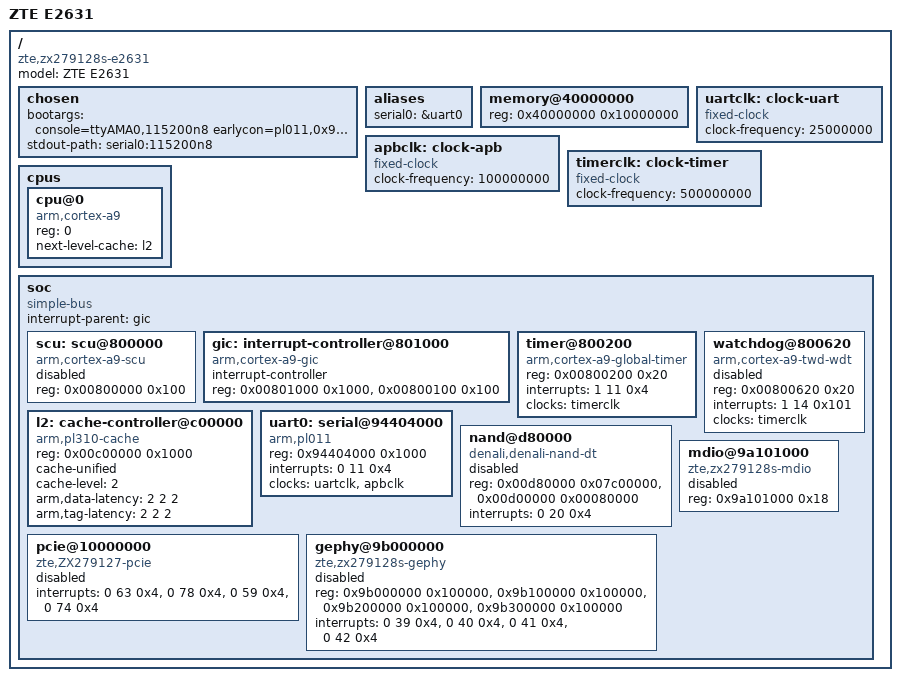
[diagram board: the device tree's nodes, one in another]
// SPDX-License-Identifier: GPL-2.0-only OR BSD-2-Clause
/dts-v1/;

/ {
	#address-cells = <1>;
	#size-cells = <1>;
	model = "ZTE E2631";
	compatible = "zte,zx279128s-e2631", "zte,zx279128-smp";

	chosen {
		bootargs = "console=ttyAMA0,115200n8 earlycon=pl011,0x94404000 loglevel=8 ignore_loglevel";
		stdout-path = "serial0:115200n8";
	};

	aliases {
		serial0 = &uart0;
	};

	memory@40000000 {
		device_type = "memory";
		reg = <0x40000000 0x10000000>;
	};

	uartclk: clock-uart {
		compatible = "fixed-clock";
		#clock-cells = <0>;
		clock-frequency = <25000000>;
	};

	apbclk: clock-apb {
		compatible = "fixed-clock";
		#clock-cells = <0>;
		clock-frequency = <100000000>;
	};

	timerclk: clock-timer {
		compatible = "fixed-clock";
		#clock-cells = <0>;
		clock-frequency = <500000000>;
	};

	cpus {
		#address-cells = <1>;
		#size-cells = <0>;

		cpu@0 {
			compatible = "arm,cortex-a9";
			device_type = "cpu";
			reg = <0>;
			next-level-cache = <&l2>;
		};
	};

	soc {
		#address-cells = <1>;
		#size-cells = <1>;
		compatible = "simple-bus";
		interrupt-parent = <&gic>;
		ranges;

		scu: scu@800000 {
			compatible = "arm,cortex-a9-scu";
			reg = <0x00800000 0x100>;
			status = "disabled";
		};

		gic: interrupt-controller@801000 {
			compatible = "arm,cortex-a9-gic";
			#interrupt-cells = <3>;
			#address-cells = <1>;
			#size-cells = <1>;
			interrupt-controller;
			reg = <0x00801000 0x1000>,
			      <0x00800100 0x100>;
		};

		timer@800200 {
			compatible = "arm,cortex-a9-global-timer";
			reg = <0x00800200 0x20>;
			interrupts = <1 11 0x4>;
			clocks = <&timerclk>;
		};

		watchdog@800620 {
			compatible = "arm,cortex-a9-twd-wdt";
			reg = <0x00800620 0x20>;
			interrupts = <1 14 0x101>;
			clocks = <&timerclk>;
			status = "disabled";
		};

		l2: cache-controller@c00000 {
			compatible = "arm,pl310-cache";
			reg = <0x00c00000 0x1000>;
			cache-unified;
			cache-level = <2>;
			arm,data-latency = <2 2 2>;
			arm,tag-latency = <2 2 2>;
		};

		uart0: serial@94404000 {
			compatible = "arm,pl011", "arm,primecell";
			reg = <0x94404000 0x1000>;
			interrupts = <0 11 0x4>;
			clocks = <&uartclk>, <&apbclk>;
			clock-names = "uartclk", "apb_pclk";
			status = "okay";
		};

		nand@d80000 {
			#address-cells = <1>;
			#size-cells = <1>;
			compatible = "denali,denali-nand-dt";
			reg = <0x00d80000 0x07c00000>,
			      <0x00d00000 0x00080000>;
			reg-names = "nand_data", "denali_reg";
			interrupts = <0 20 0x4>;
			status = "disabled";
		};

		pcie@10000000 {
			compatible = "zte,ZX279127-pcie";
			interrupts = <0 63 0x4>, <0 78 0x4>,
				     <0 59 0x4>, <0 74 0x4>;
			status = "disabled";
		};

		mdio@9a101000 {
			compatible = "zte,zx279128s-mdio";
			reg = <0x9a101000 0x18>;
			status = "disabled";
		};

		gephy@9b000000 {
			compatible = "zte,zx279128s-gephy";
			reg = <0x9b000000 0x100000>,
			      <0x9b100000 0x100000>,
			      <0x9b200000 0x100000>,
			      <0x9b300000 0x100000>;
			interrupts = <0 39 0x4>, <0 40 0x4>,
				     <0 41 0x4>, <0 42 0x4>;
			status = "disabled";
		};
	};
};
